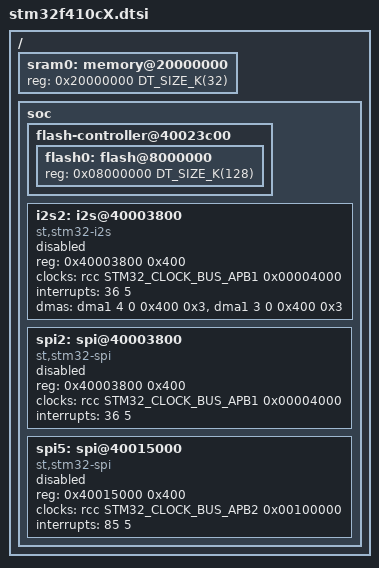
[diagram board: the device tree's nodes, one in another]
/*
 * Copyright (c) 2023 Findlay Feng
 *
 * SPDX-License-Identifier: Apache-2.0
 */

#include <mem.h>
#include <st/f4/stm32f410.dtsi>

/ {
	sram0: memory@20000000 {
		reg = <0x20000000 DT_SIZE_K(32)>;
	};

	soc {
		flash-controller@40023c00 {
			flash0: flash@8000000 {
				reg = <0x08000000 DT_SIZE_K(128)>;
			};
		};

		i2s2: i2s@40003800 {
			compatible = "st,stm32-i2s";
			#address-cells = <1>;
			#size-cells = <0>;
			reg = <0x40003800 0x400>;
			clocks = <&rcc STM32_CLOCK_BUS_APB1 0x00004000>;
			interrupts = <36 5>;
			dmas = <&dma1 4 0 0x400 0x3
				&dma1 3 0 0x400 0x3>;
			dma-names = "tx", "rx";
			status = "disabled";
		};

		spi2: spi@40003800 {
			compatible = "st,stm32-spi";
			#address-cells = <1>;
			#size-cells = <0>;
			reg = <0x40003800 0x400>;
			clocks = <&rcc STM32_CLOCK_BUS_APB1 0x00004000>;
			interrupts = <36 5>;
			status = "disabled";
		};

		spi5: spi@40015000 {
			compatible = "st,stm32-spi";
			#address-cells = <1>;
			#size-cells = <0>;
			reg = <0x40015000 0x400>;
			clocks = <&rcc STM32_CLOCK_BUS_APB2 0x00100000>;
			interrupts = <85 5>;
			status = "disabled";
		};
	};
};
